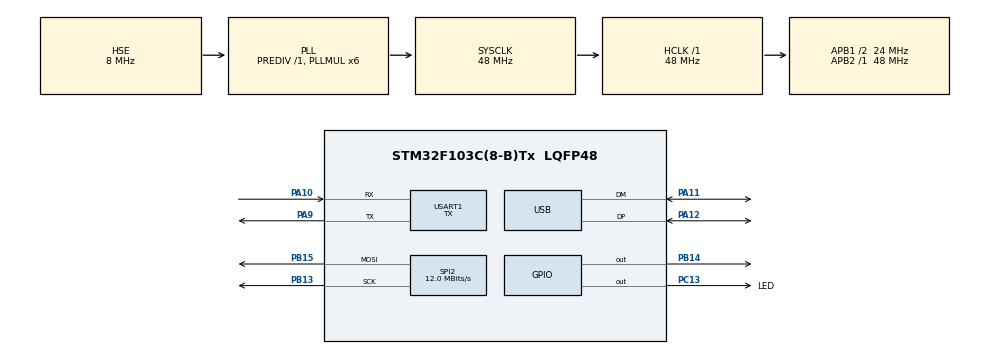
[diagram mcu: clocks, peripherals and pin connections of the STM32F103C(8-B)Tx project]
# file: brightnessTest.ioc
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Mcu.Family=STM32F1
Mcu.Name=STM32F103C(8-B)Tx
Mcu.Package=LQFP48
NVIC.PriorityGroup=NVIC_PRIORITYGROUP_4
NVIC.USART1_IRQn=true\:0\:0\:false\:false\:true\:true\:true
PA10.Mode=Asynchronous
PA10.Signal=USART1_RX
PA11.Mode=Device
PA11.Signal=USB_DM
PA12.Mode=Device
PA12.Signal=USB_DP
PA13.Mode=Trace_Asynchronous_SW
PA13.Signal=SYS_JTMS-SWDIO
PA14.Mode=Trace_Asynchronous_SW
PA14.Signal=SYS_JTCK-SWCLK
PA9.Mode=Asynchronous
PA9.Signal=USART1_TX
PB13.Mode=TX_Only_Simplex_Unidirect_Master
PB13.Signal=SPI2_SCK
PB14.Signal=GPIO_Output
PB15.Mode=TX_Only_Simplex_Unidirect_Master
PB15.Signal=SPI2_MOSI
PB3.Mode=Trace_Asynchronous_SW
PB3.Signal=SYS_JTDO-TRACESWO
PC13-TAMPER-RTC.GPIO_Label=LED
PC13-TAMPER-RTC.GPIO_ModeDefaultOutputPP=GPIO_MODE_OUTPUT_OD
PC13-TAMPER-RTC.GPIO_PuPd=GPIO_PULLUP
PC13-TAMPER-RTC.PinState=GPIO_PIN_SET
PC13-TAMPER-RTC.Signal=GPIO_Output
PC14-OSC32_IN.Mode=LSE-External-Oscillator
PC14-OSC32_IN.Signal=RCC_OSC32_IN
PC15-OSC32_OUT.Mode=LSE-External-Oscillator
PC15-OSC32_OUT.Signal=RCC_OSC32_OUT
PD0-OSC_IN.Mode=HSE-External-Oscillator
PD0-OSC_IN.Signal=RCC_OSC_IN
PD1-OSC_OUT.Mode=HSE-External-Oscillator
PD1-OSC_OUT.Signal=RCC_OSC_OUT
ProjectManager.HeapSize=0x200
ProjectManager.StackSize=0x400
ProjectManager.TargetToolchain=STM32CubeIDE
RCC.AHBFreq_Value=48000000
RCC.APB1CLKDivider=RCC_HCLK_DIV2
RCC.APB1Freq_Value=24000000
RCC.APB1TimFreq_Value=48000000
RCC.APB2Freq_Value=48000000
RCC.APB2TimFreq_Value=48000000
RCC.HCLKFreq_Value=48000000
RCC.PLLMUL=RCC_PLL_MUL6
RCC.SYSCLKFreq_VALUE=48000000
RCC.SYSCLKSource=RCC_SYSCLKSOURCE_PLLCLK
RCC.USBFreq_Value=48000000
SPI2.CalculateBaudRate=12.0 MBits/s
SPI2.DataSize=SPI_DATASIZE_16BIT
SPI2.Direction=SPI_DIRECTION_2LINES
SPI2.Mode=SPI_MODE_MASTER
SPI2.VirtualType=VM_MASTER
USART1.Mode=MODE_TX
USART1.VirtualMode=VM_ASYNC
board=custom

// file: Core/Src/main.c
/* USER CODE BEGIN Header */
/**
  ******************************************************************************
  * @file           : main.c
  * @brief          : Main program body
  ******************************************************************************
  * @attention
  *
  * <h2><center>&copy; Copyright (c) 2020 STMicroelectronics.
  * All rights reserved.</center></h2>
  *
  * This software component is licensed by ST under BSD 3-Clause license,
  * the "License"; You may not use this file except in compliance with the
  * License. You may obtain a copy of the License at:
  *                        opensource.org/licenses/BSD-3-Clause
  *
  ******************************************************************************
  */
/* USER CODE END Header */
#include "main.h"

/* USER CODE BEGIN Includes */
#include <string.h>
/* USER CODE END Includes */

SPI_HandleTypeDef hspi2;

UART_HandleTypeDef huart1;

PCD_HandleTypeDef hpcd_USB_FS;

void SystemClock_Config(void);
static void MX_GPIO_Init(void);
static void MX_SPI2_Init(void);
static void MX_USART1_UART_Init(void);
static void MX_USB_PCD_Init(void);

int main(void)
{

  /* MCU Configuration--------------------------------------------------------*/

  /* Reset of all peripherals, Initializes the Flash interface and the Systick. */
  HAL_Init();

  /* Configure the system clock */
  SystemClock_Config();

  /* Initialize all configured peripherals */
  MX_GPIO_Init();
  MX_SPI2_Init();
  MX_USART1_UART_Init();
  MX_USB_PCD_Init();
  /* USER CODE BEGIN 2 */
  char message[] = "UART serial works!\n";

  /* USER CODE END 2 */

  /* Infinite loop */
  /* USER CODE BEGIN WHILE */
  while (1)
  {
    if (HAL_UART_Transmit_IT(&huart1, message, strlen(message)) != HAL_OK) {
      Error_Handler();
    }
    HAL_GPIO_TogglePin(LED_GPIO_Port, LED_Pin);
    HAL_Delay(1000);
    /* USER CODE END WHILE */

  }
}

void SystemClock_Config(void)
{
  RCC_OscInitTypeDef RCC_OscInitStruct = {0};
  RCC_ClkInitTypeDef RCC_ClkInitStruct = {0};
  RCC_PeriphCLKInitTypeDef PeriphClkInit = {0};

  /** Initializes the RCC Oscillators according to the specified parameters
  * in the RCC_OscInitTypeDef structure.
  */
  RCC_OscInitStruct.OscillatorType = RCC_OSCILLATORTYPE_HSE;
  RCC_OscInitStruct.HSEState = RCC_HSE_ON;
  RCC_OscInitStruct.HSEPredivValue = RCC_HSE_PREDIV_DIV1;
  RCC_OscInitStruct.HSIState = RCC_HSI_ON;
  RCC_OscInitStruct.PLL.PLLState = RCC_PLL_ON;
  RCC_OscInitStruct.PLL.PLLSource = RCC_PLLSOURCE_HSE;
  RCC_OscInitStruct.PLL.PLLMUL = RCC_PLL_MUL6;
  if (HAL_RCC_OscConfig(&RCC_OscInitStruct) != HAL_OK)
  {
    Error_Handler();
  }
  /** Initializes the CPU, AHB and APB buses clocks
  */
  RCC_ClkInitStruct.ClockType = RCC_CLOCKTYPE_HCLK|RCC_CLOCKTYPE_SYSCLK
                              |RCC_CLOCKTYPE_PCLK1|RCC_CLOCKTYPE_PCLK2;
  RCC_ClkInitStruct.SYSCLKSource = RCC_SYSCLKSOURCE_PLLCLK;
  RCC_ClkInitStruct.AHBCLKDivider = RCC_SYSCLK_DIV1;
  RCC_ClkInitStruct.APB1CLKDivider = RCC_HCLK_DIV2;
  RCC_ClkInitStruct.APB2CLKDivider = RCC_HCLK_DIV1;

  if (HAL_RCC_ClockConfig(&RCC_ClkInitStruct, FLASH_LATENCY_1) != HAL_OK)
  {
    Error_Handler();
  }
  PeriphClkInit.PeriphClockSelection = RCC_PERIPHCLK_USB;
  PeriphClkInit.UsbClockSelection = RCC_USBCLKSOURCE_PLL;
  if (HAL_RCCEx_PeriphCLKConfig(&PeriphClkInit) != HAL_OK)
  {
    Error_Handler();
  }
}

static void MX_SPI2_Init(void)
{

  /* SPI2 parameter configuration*/
  hspi2.Instance = SPI2;
  hspi2.Init.Mode = SPI_MODE_MASTER;
  hspi2.Init.Direction = SPI_DIRECTION_2LINES;
  hspi2.Init.DataSize = SPI_DATASIZE_16BIT;
  hspi2.Init.CLKPolarity = SPI_POLARITY_LOW;
  hspi2.Init.CLKPhase = SPI_PHASE_1EDGE;
  hspi2.Init.NSS = SPI_NSS_SOFT;
  hspi2.Init.BaudRatePrescaler = SPI_BAUDRATEPRESCALER_2;
  hspi2.Init.FirstBit = SPI_FIRSTBIT_MSB;
  hspi2.Init.TIMode = SPI_TIMODE_DISABLE;
  hspi2.Init.CRCCalculation = SPI_CRCCALCULATION_DISABLE;
  hspi2.Init.CRCPolynomial = 10;
  if (HAL_SPI_Init(&hspi2) != HAL_OK)
  {
    Error_Handler();
  }

}

static void MX_USART1_UART_Init(void)
{

  huart1.Instance = USART1;
  huart1.Init.BaudRate = 115200;
  huart1.Init.WordLength = UART_WORDLENGTH_8B;
  huart1.Init.StopBits = UART_STOPBITS_1;
  huart1.Init.Parity = UART_PARITY_NONE;
  huart1.Init.Mode = UART_MODE_TX;
  huart1.Init.HwFlowCtl = UART_HWCONTROL_NONE;
  huart1.Init.OverSampling = UART_OVERSAMPLING_16;
  if (HAL_UART_Init(&huart1) != HAL_OK)
  {
    Error_Handler();
  }

}

static void MX_USB_PCD_Init(void)
{

  hpcd_USB_FS.Instance = USB;
  hpcd_USB_FS.Init.dev_endpoints = 8;
  hpcd_USB_FS.Init.speed = PCD_SPEED_FULL;
  hpcd_USB_FS.Init.low_power_enable = DISABLE;
  hpcd_USB_FS.Init.lpm_enable = DISABLE;
  hpcd_USB_FS.Init.battery_charging_enable = DISABLE;
  if (HAL_PCD_Init(&hpcd_USB_FS) != HAL_OK)
  {
    Error_Handler();
  }

}

static void MX_GPIO_Init(void)
{
  GPIO_InitTypeDef GPIO_InitStruct = {0};

  /* GPIO Ports Clock Enable */
  __HAL_RCC_GPIOC_CLK_ENABLE();
  __HAL_RCC_GPIOD_CLK_ENABLE();
  __HAL_RCC_GPIOB_CLK_ENABLE();
  __HAL_RCC_GPIOA_CLK_ENABLE();

  /*Configure GPIO pin Output Level */
  HAL_GPIO_WritePin(LED_GPIO_Port, LED_Pin, GPIO_PIN_SET);

  /*Configure GPIO pin Output Level */
  HAL_GPIO_WritePin(GPIOB, GPIO_PIN_14, GPIO_PIN_RESET);

  /*Configure GPIO pin : LED_Pin */
  GPIO_InitStruct.Pin = LED_Pin;
  GPIO_InitStruct.Mode = GPIO_MODE_OUTPUT_OD;
  GPIO_InitStruct.Pull = GPIO_PULLUP;
  GPIO_InitStruct.Speed = GPIO_SPEED_FREQ_LOW;
  HAL_GPIO_Init(LED_GPIO_Port, &GPIO_InitStruct);

  /*Configure GPIO pin : PB14 */
  GPIO_InitStruct.Pin = GPIO_PIN_14;
  GPIO_InitStruct.Mode = GPIO_MODE_OUTPUT_PP;
  GPIO_InitStruct.Pull = GPIO_NOPULL;
  GPIO_InitStruct.Speed = GPIO_SPEED_FREQ_LOW;
  HAL_GPIO_Init(GPIOB, &GPIO_InitStruct);

}

void Error_Handler(void)
{
  /* USER CODE BEGIN Error_Handler_Debug */
  /* User can add his own implementation to report the HAL error return state */
  while (1) {
    HAL_GPIO_TogglePin(LED_GPIO_Port, LED_Pin);
    HAL_Delay(200);
  }
  /* USER CODE END Error_Handler_Debug */
}

/************************ (C) COPYRIGHT STMicroelectronics *****END OF FILE****/
